# SAM9X75D1GN2 device description
Architecture: ARM926EJ-S; Family: SAM9; Series: SAM9X7
Registers are 32-bit, read-write, reset 0x0 unless marked. A register's access mark holds for its fields unless they carry their own. Offsets are from the block's base; [hi:lo] are bit positions; lines under a group give offsets from that group; {n}, {i} and the like mark numbered series; 'fields as' and 'values as' point back to an identical list.

## ISC — Image Sensor Controller
Instances: ISC 0xF8048000
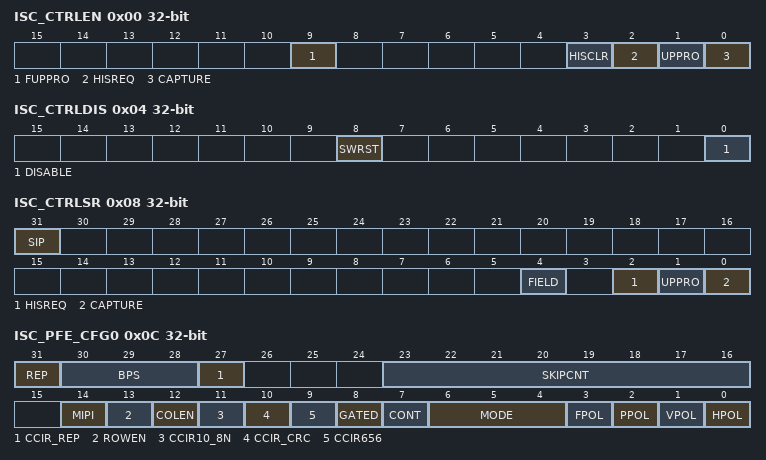
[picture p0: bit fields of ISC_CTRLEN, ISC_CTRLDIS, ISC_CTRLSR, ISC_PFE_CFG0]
0x00 ISC_CTRLEN wo reset not defined (atomic set of ISC_CTRLSR) — Control Enable Register
  [9] FUPPRO — Force Update Color Profile
  [3] HISCLR — Histogram Table Clear
  [2] HISREQ — Histogram Update Request
  [1] UPPRO — Update Color Profile
  [0] CAPTURE — Single Shot or Multiple Frame Capture Input Stream Command
0x04 ISC_CTRLDIS wo reset not defined (atomic clear of ISC_CTRLSR) — Control Disable Register
  [8] SWRST — Software Reset
  [0] DISABLE — End Capture At Next Vertical Synchronization Detection
0x08 ISC_CTRLSR ro — Control Status Register
  [31] SIP — Synchronization In Progress
    0=The double domain synchronization is terminated; 1=The double domain synchronization is in progress
  [4] FIELD — Field Status (only relevant when the video stream is interlaced)
    0=The current field/segment is a top field; 1=The current field/segment is a bottom field
  [2] HISREQ — Histogram Request Pending
    0=There is no histogram pending request; 1=Indicates that the histogram request is still pending
  [1] UPPRO — Profile Update Pending
    0=There is no profile update pending request; 1=Indicates that the profile update request is still pending
  [0] CAPTURE — Capture Pending
    0=Capture mode is disabled; 1=Capture is pending
0x0C ISC_PFE_CFG0 — Parallel Front End Configuration 0 Register
  [31] REP — Up Multiply with Replication
    0=Unused bits are stuck at 0; 1=Unused bits are copied from MSB
  [30:28] BPS — Bits Per Sample
    0=TWELVE (12-bit input); 1=ELEVEN (11-bit input); 2=TEN (10-bit input); 3=NINE (9-bit input); 4=EIGHT (8-bit input); 5=FORTY (40-bit input (used for MIPI formats up to forty bits per pixel))
  [27] CCIR_REP — CCIR Replication
    values as REP
  [23:16] SKIPCNT — Frame Skipping Counter
  [14] MIPI — MIPI Interface Connection
    0=Input data come from the physical parallel interface; 1=Input data come from the physical MIPI interface
  [13] ROWEN — Row Cropping Enable
    0=Row Cropping is disabled; 1=Row Cropping is enabled
  [12] COLEN — Column Cropping Enable
    0=Column Cropping is disabled; 1=Column Cropping is enabled
  [11] CCIR10_8N — CCIR 10 bits or 8 bits
    0=8-bit mode; 1=10-bit mode
  [10] CCIR_CRC — CCIR656 CRC Decoder
    0=Embedded CRC is discarded; 1=Embedded CRC is decoded
  [9] CCIR656 — CCIR656 input mode
    0=HSYNC and VSYNC signals are used to synchronize the input stream; 1=Embedded synchronization is used
  [8] GATED — Gated input clock
    0=The external pixel clock is free running; 1=The external pixel clock is gated
  [7] CONT — Continuous Acquisition
    0=Single Shot mode; 1=Video mode
  [6:4] MODE — Parallel Front End Mode
    0=PROGRESSIVE (Video source is progressive.); 1=DF_TOP (Video source is interlaced, two fields are captured starting with top field.); 2=DF_BOTTOM (Video source is interlaced, two fields are captured starting with bottom field.); 3=DF_IMMEDIATE (Video source is interlaced, two fields are captured immediately.); 4=SF_TOP (Video source is interlaced, one field is captured starting with the top field.); 5=SF_BOTTOM (Video source is interlaced, one field is captured starting with the bottom field.); 6=SF_IMMEDIATE (Video source is interlaced, one field is captured starting immediately.)
  [3] FPOL — Field Polarity
    0=Top field is sampled when F value is 0; Bottom field is sampled when F value is 1; 1=Top field is sampled when F value is 1; Bottom field is sampled when F value is 0
  [2] PPOL — Pixel Clock Polarity
    0=The pixel stream is sampled on the rising edge of the pixel clock; 1=The pixel stream is sampled on the falling edge of the pixel clock
  [1] VPOL — Vertical Synchronization Polarity
    0=VSYNC signal is active high, i.e. valid pixels are sampled when VSYNC is asserted.; 1=VSYNC signal is active low, i.e. valid pixels are sampled when VSYNC is deasserted.
  [0] HPOL — Horizontal Synchronization Polarity
    0=HSYNC signal is active high, i.e. valid pixels are sampled when HSYNC is asserted.; 1=HSYNC signal is active low, i.e. valid pixels are sampled when HSYNC is deasserted.
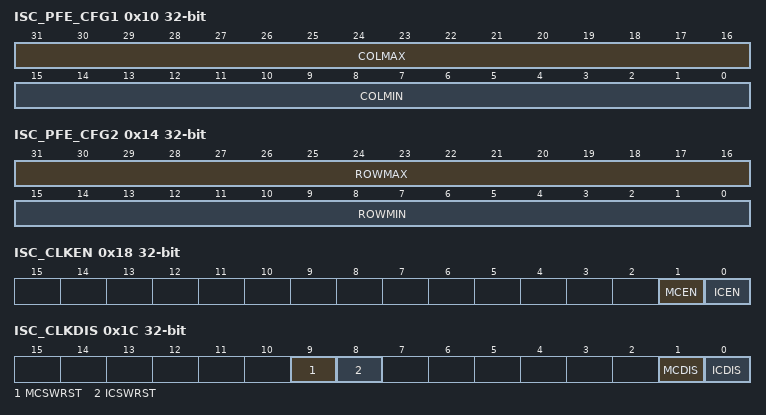
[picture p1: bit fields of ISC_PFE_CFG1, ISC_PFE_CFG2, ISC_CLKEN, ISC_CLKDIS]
0x10 ISC_PFE_CFG1 — Parallel Front End Configuration 1 Register
  [31:16] COLMAX — Column Maximum Limit
  [15:0] COLMIN — Column Minimum Limit
0x14 ISC_PFE_CFG2 — Parallel Front End Configuration 2 Register
  [31:16] ROWMAX — Row Maximum Limit
  [15:0] ROWMIN — Row Minimum Limit
0x18 ISC_CLKEN wo reset not defined (atomic set of ISC_CLKSR) — Clock Enable Register
  [1] MCEN — Camera Sensor Clock Domain Enable
    0=No effect; 1=Enables the camera sensor clock
  [0] ICEN — ISP Clock Enable
    0=No effect; 1=Enables the ISP clock
0x1C ISC_CLKDIS wo reset not defined (atomic clear of ISC_CLKSR) — Clock Disable Register
  [9] MCSWRST — Camera Sensor Clock Domain Software Reset
  [8] ICSWRST — ISP Clock Software Reset
  [1] MCDIS — Camera Sensor Clock Domain Disable
  [0] ICDIS — ISP Clock Disable
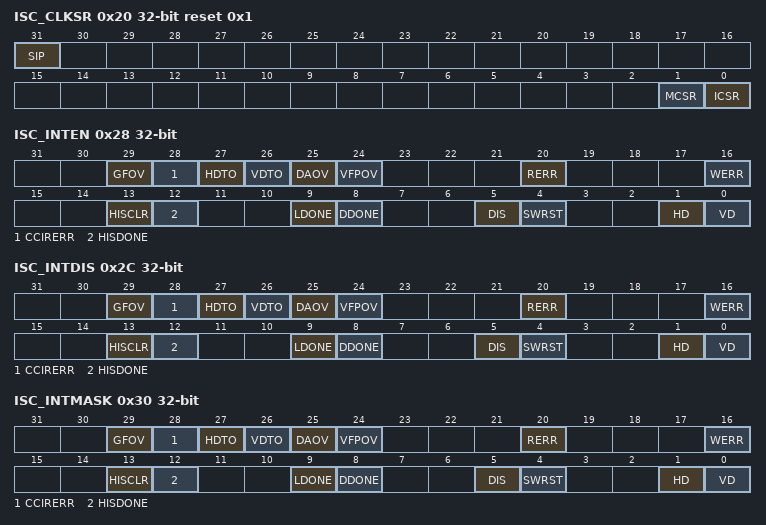
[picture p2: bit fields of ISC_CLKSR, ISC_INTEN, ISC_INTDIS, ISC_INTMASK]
0x20 ISC_CLKSR ro reset 0x1 — Clock Status Register
  [31] SIP — Synchronization In Progress
    0=The double domain synchronization operation is over; 1=The double domain synchronization operation is in progress
  [1] MCSR — Camera Sensor Clock Status Register
    0=The camera sensor clock is disabled; 1=The camera sensor clock is enabled
  [0] ICSR — ISP Clock Status Register
    0=The ISP clock is disabled; 1=The ISP clock is enabled
0x24 ISC_CLKCFG — Clock Configuration Register
  [23:16] MCDIV — Camera Sensor Reference Clock Divider
0x28 ISC_INTEN wo reset not defined (atomic set of ISC_INTSR) — Interrupt Enable Register
  [29] GFOV — Input FIFO Overflow Interrupt Enable
  [28] CCIRERR — CCIR Decoder Error Interrupt Enable
  [27] HDTO — Horizontal Synchronization Timeout Interrupt Enable
  [26] VDTO — Vertical Synchronization Timeout Interrupt Enable
  [25] DAOV — Data Overflow Interrupt Enable
  [24] VFPOV — Vertical Front Porch Overflow Interrupt Enable
  [20] RERR — Read Channel Error Interrupt Enable
  [16] WERR — Write Channel Error Interrupt Enable
  [13] HISCLR — Histogram Clear Interrupt Enable
  [12] HISDONE — Histogram Completed Interrupt Enable
  [9] LDONE — DMA List Done Interrupt Enable
  [8] DDONE — DMA Done Interrupt Enable
  [5] DIS — Disable Completed Interrupt Enable
  [4] SWRST — Software Reset Completed Interrupt Enable
  [1] HD — Horizontal Synchronization Detection Interrupt Enable
  [0] VD — Vertical Synchronization Detection Interrupt Enable
0x2C ISC_INTDIS wo reset not defined (atomic clear of ISC_INTSR) — Interrupt Disable Register
  [29] GFOV — FIFO Overflow Interrupt Disable
  [28] CCIRERR — CCIR Decoder Error Interrupt Disable
  [27] HDTO — Horizontal Synchronization Timeout Interrupt Disable
  [26] VDTO — Vertical Synchronization Timeout Interrupt Disable
  [25] DAOV — Data Overflow Interrupt Disable
  [24] VFPOV — Vertical Front Porch Overflow Interrupt Disable
  [20] RERR — Read Channel Error Interrupt Disable
  [16] WERR — Write Channel Error Interrupt Disable
  [13] HISCLR — Histogram Clear Interrupt Disable
  [12] HISDONE — Histogram Completed Interrupt Disable
  [9] LDONE — DMA List Done Interrupt Disable
  [8] DDONE — DMA Done Interrupt Disable
  [5] DIS — Disable Completed Interrupt Disable
  [4] SWRST — Software Reset Completed Interrupt Disable
  [1] HD — Horizontal Synchronization Detection Interrupt Disable
  [0] VD — Vertical Synchronization Detection Interrupt Disable
0x30 ISC_INTMASK ro — Interrupt Mask Register
  [29] GFOV — FIFO Overflow Interrupt Mask
  [28] CCIRERR — CCIR Decoder Error Interrupt Mask
  [27] HDTO — Horizontal Synchronization Timeout Interrupt Mask
  [26] VDTO — Vertical Synchronization Timeout Interrupt Mask
  [25] DAOV — Data Overflow Interrupt Mask
  [24] VFPOV — Vertical Front Porch Overflow Interrupt Mask
  [20] RERR — Read Channel Error Interrupt Mask
  [16] WERR — Write Channel Error Interrupt Mask
  [13] HISCLR — Histogram Clear Interrupt Mask
  [12] HISDONE — Histogram Completed Interrupt Mask
  [9] LDONE — DMA List Done Interrupt Mask
  [8] DDONE — DMA Done Interrupt Mask
  [5] DIS — Disable Completed Interrupt Mask
  [4] SWRST — Software Reset Completed Interrupt Mask
  [1] HD — Horizontal Synchronization Detection Interrupt Mask
  [0] VD — Vertical Synchronization Detection Interrupt Mask
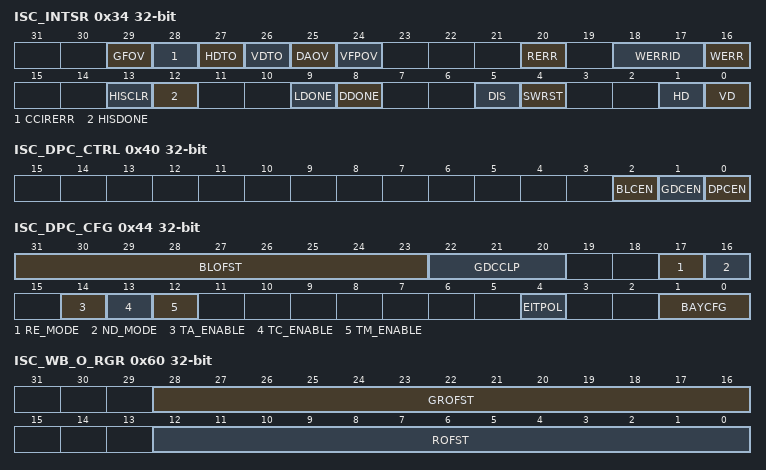
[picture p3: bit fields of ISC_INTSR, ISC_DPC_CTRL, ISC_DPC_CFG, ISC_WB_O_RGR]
0x34 ISC_INTSR ro — Interrupt Status Register
  [29] GFOV — FIFO Overflow Interrupt (relevant if MIPI interface is not selected) (cleared on read)
    0=No FIFO overflow detected since the last read of the Interrupt Status register; 1=A FIFO overflow has been detected
  [28] CCIRERR — CCIR Decoder Error Interrupt (cleared on read)
    0=No CCIR CRC error detected since the last read of the Interrupt Status register; 1=A CCIR CRC error has been detected
  [27] HDTO — Horizontal Synchronization Timeout Interrupt (cleared on read)
    0=Horizontal synchronization is detected since the last reset of the Interrupt Status register; 1=No horizontal synchronization is detected
  [26] VDTO — Vertical Synchronization Timeout Interrupt (cleared on read)
    0=A vertical synchronization is detected since the last reset of the Interrupt Status register; 1=No vertical synchronization is detected
  [25] DAOV — Data Overflow Interrupt (cleared on read)
    0=No data overflow error occurred since the last reset of the Interrupt Status register; 1=A data overflow occurred
  [24] VFPOV — Vertical Front Porch Overflow Interrupt (cleared on read)
    0=No vertical front porch error occurred since the last read of the Interrupt Status register; 1=The vertical synchronization has been detected but the DMA channel is still busy
  [20] RERR — Read Channel Error Interrupt (cleared on read)
    0=No read channel error since the last read of the Interrupt Status register; 1=A read channel error occurred when the ISC read the descriptor
  [18:17] WERRID — Write Channel Error Identifier
    0=CH0 (An error occurred for Channel 0 (RAW/RGB/Y)); 1=CH1 (An error occurred for Channel 1 (CbCr/Cb)); 2=CH2 (An error occurred for Channel 2 (Cr)); 3=WB (Write back channel error)
  [16] WERR — Write Channel Error Interrupt (cleared on read)
    0=No write channel error since the last read of the Interrupt Status register; 1=A write channel error occurred
  [13] HISCLR — Histogram Clear Interrupt (cleared on read)
    0=No Histogram Clear interrupt has been raised since the last read of the Interrupt Status register; 1=The Histogram Clear interrupt has occurred
  [12] HISDONE — Histogram Completed Interrupt (cleared on read)
    0=No Histogram Completed interrupt has been raised since the last read of the Interrupt Status register; 1=The Histogram Completed interrupt has occurred
  [9] LDONE — DMA List Done Interrupt (cleared on read)
    0=No DMA List Done interrupt has occurred since the last read of the Interrupt Status register; 1=The DMA List Done interrupt has occurred
  [8] DDONE — DMA Done Interrupt (cleared on read)
    0=No DMA Transfer Done interrupt has occurred since the last read of the Interrupt Status register; 1=The DMA Transfer Done interrupt has occurred
  [5] DIS — Disable Completed Interrupt (cleared on read)
    0=The disable has not occurred since the last read of the Interrupt Status register; 1=The disable has completed
  [4] SWRST — Software Reset Completed Interrupt (cleared on read)
    0=No software reset completion since the last read of the Interrupt Status register; 1=The software reset has completed
  [1] HD — Horizontal Synchronization Detected Interrupt (cleared on read)
    0=No horizontal synchronization detection since the last read of the Interrupt Status register; 1=A horizontal synchronization has been detected
  [0] VD — Vertical Synchronization Detected Interrupt (cleared on read)
    0=No vertical synchronization detection since the last read of the Interrupt Status register; 1=A vertical synchronization has been detected
0x40 ISC_DPC_CTRL — Defective Pixel Correction Control Register
  [2] BLCEN — Black Level Correction Enable
    0=Black level correction is disabled; 1=Black level correction is enabled
  [1] GDCEN — Green Disparity Correction Enable
    0=Green disparity correction is disabled; 1=Green disparity correction is enabled
  [0] DPCEN — Defective Pixel Correction Enable
    0=Defective pixel correction is disabled; 1=Defective pixel correction is enabled
0x44 ISC_DPC_CFG — Defective Pixel Correction Configuration Register
  [31:23] BLOFST — Black Level Offset Value
  [22:20] GDCCLP — Green Disparity Clipping Value
  [17] RE_MODE — Replacement Algorithm
    0=Median pixel is used; 1=Average pixel is used
  [16] ND_MODE — Noise Detection Mode
    0=At least one detector flag is necessary to trigger the correction; 1=All detector flags are required to trigger the correction
  [14] TA_ENABLE — Average Threshold Enable
    0=Average detector is disabled; 1=Average detector is enabled
  [13] TC_ENABLE — Closest Pixels Threshold Enable
    0=Closest Pixels detector is disabled; 1=Closest Pixels detector is enabled
  [12] TM_ENABLE — Median Threshold Enable
    0=Median detector is disabled; 1=Median detector is enabled
  [4] EITPOL — Edge Interpolation
    0=No edge interpolation is performed; 1=Edge interpolation is performed
  [1:0] BAYCFG — Color Filter Array Pattern
    0=GRGR (Starting row configuration is G R G R (red row)); 1=RGRG (Starting row configuration is R G R G (red row)); 2=GBGB (Starting row configuration is G B G B (blue row)); 3=BGBG (Starting row configuration is B G B G (blue row))
0x48 ISC_DPC_THRESHM — Defective Pixel Correction Threshold M Register
  [11:0] THRESHM — Median Threshold
0x4C ISC_DPC_THRESHC — Defective Pixel Correction Threshold C Register
  [11:0] THRESHC — Closest Pixel Threshold
0x50 ISC_DPC_THRESHA — Defective Pixel Correction Threshold A Register
  [11:0] THRESHA — Average Threshold
0x54 ISC_DPC_SR ro — Defective Pixel Correction Status Register
  [23:0] COUNTER — Defective Pixel Counter (cleared on read)
0x58 ISC_WB_CTRL — White Balance Control Register
  [0] ENABLE — White Balance Enable
    0=The white balance is disabled; 1=The white balance is enabled
0x5C ISC_WB_CFG — White Balance Configuration Register
  [1:0] BAYCFG — White Balance Bayer Configuration (Pixel Color Pattern)
    0=GRGR (Starting Row configuration is G R G R (Red Row)); 1=RGRG (Starting Row configuration is R G R G (Red Row)); 2=GBGB (Starting Row configuration is G B G B (Blue Row)); 3=BGBG (Starting Row configuration is B G B G (Blue Row))
0x60 ISC_WB_O_RGR — White Balance Offset for R, GR Register
  [28:16] GROFST — Offset Green Component for Red Row (signed 13 bits 1:12:0)
  [12:0] ROFST — Offset Red Component (signed 13 bits 1:12:0)
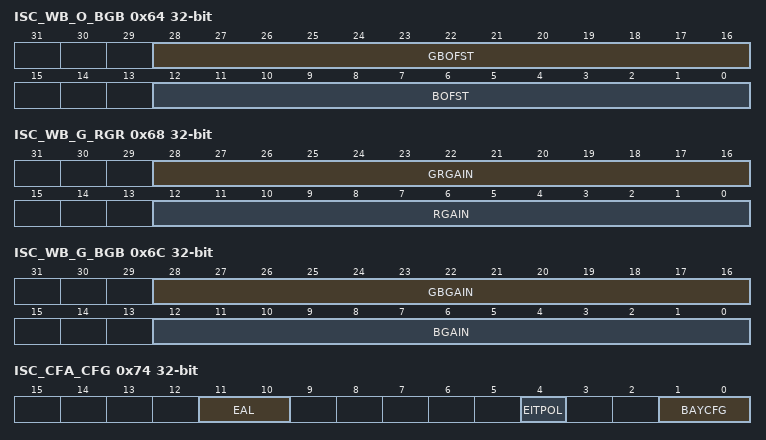
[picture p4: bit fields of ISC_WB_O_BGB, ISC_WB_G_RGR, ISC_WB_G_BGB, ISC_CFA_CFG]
0x64 ISC_WB_O_BGB — White Balance Offset for B, GB Register
  [28:16] GBOFST — Offset Green Component for Blue Row (signed 13 bits, 1:12:0)
  [12:0] BOFST — Offset Blue Component (signed 13 bits, 1:12:0)
0x68 ISC_WB_G_RGR — White Balance Gain for R, GR Register
  [28:16] GRGAIN — Green Component (Red row) Gain (unsigned 13 bits, 0:4:9)
  [12:0] RGAIN — Red Component Gain (unsigned 13 bits, 0:4:9)
0x6C ISC_WB_G_BGB — White Balance Gain for B, GB Register
  [28:16] GBGAIN — Green Component (Blue Row) Gain (unsigned 13 bits, 0:4:9)
  [12:0] BGAIN — Blue Component Gain (unsigned 13 bits, 0:4:9)
0x70 ISC_CFA_CTRL — Color Filter Array Control Register
  [0] ENABLE — Color Filter Array Interpolation Enable
    0=Color Filter Array Interpolation is disabled; 1=Color Filter Array Interpolation is enabled
0x74 ISC_CFA_CFG — Color Filter Array Configuration Register
  [11:10] EAL — Green Channel Edge Adaptive Level
    0=GLINEAR (Green plane is linearly interpolated.); 1=GMEAN (Green plane is the mean value between the linearly interpolated plane and adaptive method plane.); 2=GADAPTIVE (Green plane is interpolated with edge adaptive method.)
  [4] EITPOL — Edge Interpolation
    0=Edges are not interpolated; 1=Edge interpolation is performed
  [1:0] BAYCFG — Bayer Color Filter Array Pattern
    0=GRGR (Starting row configuration is G R G R (red row)); 1=RGRG (Starting row configuration is R G R G (red row); 2=GBGB (Starting row configuration is G B G B (blue row)); 3=BGBG (Starting row configuration is B G B G (blue row))
0x78 ISC_CC_CTRL — Color Correction Control Register
  [0] ENABLE — Color Correction Enable
    0=Color correction is disabled; 1=Color correction is enabled
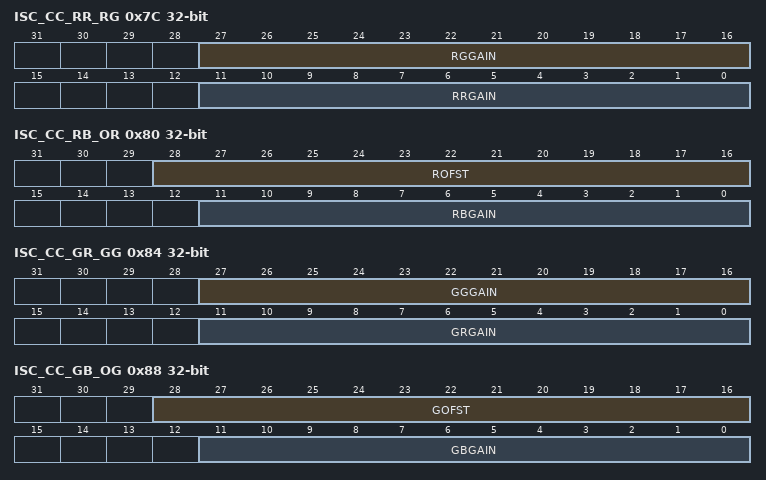
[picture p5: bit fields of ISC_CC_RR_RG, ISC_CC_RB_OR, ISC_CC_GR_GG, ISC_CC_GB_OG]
0x7C ISC_CC_RR_RG — Color Correction RR RG Register
  [27:16] RGGAIN — Green Gain for Red Component (signed 12 bits, 1:3:8)
  [11:0] RRGAIN — Red Gain for Red Component (signed 12 bits, 1:3:8)
0x80 ISC_CC_RB_OR — Color Correction RB OR Register
  [28:16] ROFST — Red Component Offset (signed 13 bits, 1:12:0)
  [11:0] RBGAIN — Blue Gain for Red Component (signed 12 bits, 1:3:8)
0x84 ISC_CC_GR_GG — Color Correction GR GG Register
  [27:16] GGGAIN — Green Gain for Green Component (signed 12 bits, 1:3:8)
  [11:0] GRGAIN — Red Gain for Green Component (signed 12 bits, 1:3:8)
0x88 ISC_CC_GB_OG — Color Correction GB OG Register
  [28:16] GOFST — Green Component Offset (signed 13 bits, 1:12:0)
  [11:0] GBGAIN — Blue Gain for Green Component (signed 12 bits, 1:3:8)
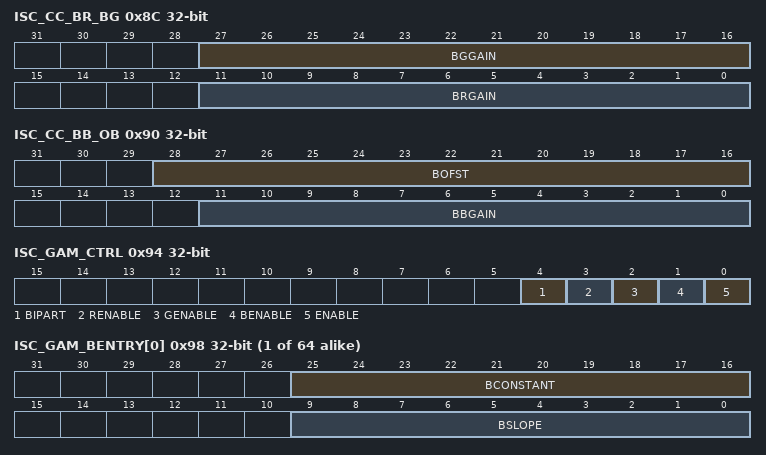
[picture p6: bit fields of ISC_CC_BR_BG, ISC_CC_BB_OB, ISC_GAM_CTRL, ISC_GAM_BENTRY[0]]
0x8C ISC_CC_BR_BG — Color Correction BR BG Register
  [27:16] BGGAIN — Green Gain for Blue Component (signed 12 bits, 1:3:8)
  [11:0] BRGAIN — Red Gain for Blue Component (signed 12 bits, 1:3:8)
0x90 ISC_CC_BB_OB — Color Correction BB OB Register
  [28:16] BOFST — Blue Component Offset (signed 13 bits, 1:12:0)
  [11:0] BBGAIN — Blue Gain for Blue Component (signed 12 bits, 1:3:8)
0x94 ISC_GAM_CTRL — Gamma Correction Control Register
  [4] BIPART — Bipartite Table Configuration
    0=Bipartite table is disabled. There are 64 points of interpolation from 0 to 4095.; 1=Bipartite table is enabled. There are 32 points of interpolation (spacing is 8) from 0 to 255, then there are 30 points of interpolation from 256 to 4095.
  [3] RENABLE — Gamma Correction Enable for R Channel
    0=12-bit to 10-bit compression is performed skipping two bits; 1=Piecewise interpolation is used to perform 12-bit to 10-bit compression for the red channel
  [2] GENABLE — Gamma Correction Enable for G Channel
    0=12-bit to 10-bit compression is performed skipping two bits; 1=Piecewise interpolation is used to perform 12-bit to 10-bit compression for the green channel
  [1] BENABLE — Gamma Correction Enable for B Channel
    0=12-bit to 10-bit compression is performed skipping two bits; 1=Piecewise interpolation is used to perform 112-bit to 10-bit compression for the blue channel
  [0] ENABLE — Gamma Correction Enable
    0=Gamma correction is disabled; 1=Gamma correction is enabled
{0x98+4i} ISC_GAM_BENTRY[{i}] (i=0..63) — Gamma Correction Blue Entry x
  [25:16] BCONSTANT — Blue Color Constant for Piecewise Interpolation (unsigned 10 bits 0:10:0)
  [9:0] BSLOPE — Blue Color Slope for Piecewise Interpolation (signed 10 bits 1:3:6)
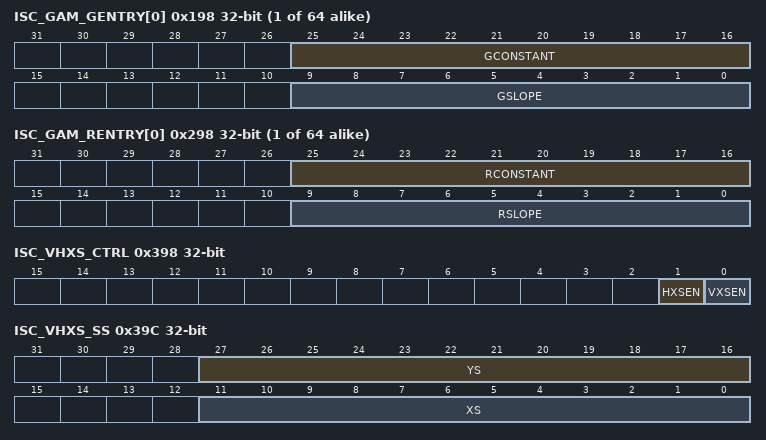
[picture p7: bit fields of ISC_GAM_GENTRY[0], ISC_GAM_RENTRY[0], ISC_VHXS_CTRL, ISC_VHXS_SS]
{0x198+4i} ISC_GAM_GENTRY[{i}] (i=0..63) — Gamma Correction Green Entry x
  [25:16] GCONSTANT — Green Color Constant for Piecewise Interpolation (unsigned 10 bits 0:10:0)
  [9:0] GSLOPE — Green Color Slope for Piecewise Interpolation (signed 10 bits 1:3:6)
{0x298+4i} ISC_GAM_RENTRY[{i}] (i=0..63) — Gamma Correction Red Entry x
  [25:16] RCONSTANT — Red Color Constant for Piecewise Interpolation (unsigned 10 bits 0:10:0)
  [9:0] RSLOPE — Red Color Slope for Piecewise Interpolation (signed 10 bits 1:3:6)
0x398 ISC_VHXS_CTRL — VHXS Control Register
  [1] HXSEN — Horizontal Scaler Enable
    0=Horizontal scaler is disabled; 1=Horizontal scaler is enabled
  [0] VXSEN — Vertical Scaler Enable
    0=Vertical scaler is disabled; 1=Vertical scaler is enabled
0x39C ISC_VHXS_SS — VHXS Source Size Register
  [27:16] YS — Source Image Vertical Size
  [11:0] XS — Source Image Horizontal Size
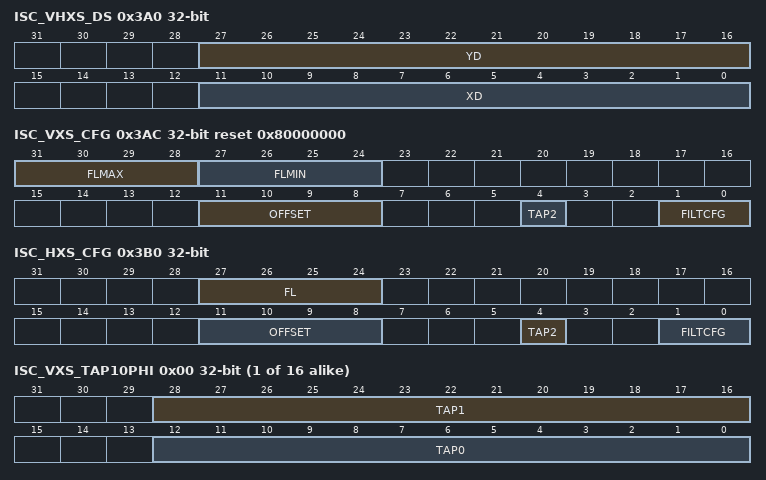
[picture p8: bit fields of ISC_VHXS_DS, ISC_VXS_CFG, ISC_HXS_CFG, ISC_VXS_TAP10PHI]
0x3A0 ISC_VHXS_DS — VHXS Destination Size Register
  [27:16] YD — Destination Image Vertical Size
  [11:0] XD — Destination Image Horizontal Size
0x3A4 ISC_VXS_FACT — VXS Scaling Factor Register
  [23:0] VFACT — Vertical Scaling Factor
0x3A8 ISC_HXS_FACT — HXS Scaling Factor Register
  [23:0] HFACT — Horizontal Scaling Factor
0x3AC ISC_VXS_CFG reset 0x80000000 — VXS Configuration Register
  [31:28] FLMAX — Flush Latency Max
  [27:24] FLMIN — Flush Latency Min
  [11:8] OFFSET — Resampling Default Phase
  [4] TAP2 — Bilinear Interpolation
    0=Custom tap values are used (see Section 8.47 "ISC VXS TAP10 Phase x [x = 0..15] Register"); 1=Bilinear interpolation is used
  [1:0] FILTCFG — Vertical Filter Initial Configuration
0x3B0 ISC_HXS_CFG — HXS Configuration Register
  [27:24] FL — Flush Latency
  [11:8] OFFSET — Resampling Default Phase
  [4] TAP2 — Bilinear Interpolation
    0=Custom tap values are used (see Section 8.49 "ISC HXS TAP10 Phase x [x = 0..15] Register"); 1=Bilinear interpolation is used
  [1:0] FILTCFG — Horizontal Filter Initial Configuration
{0x3B4+8i} ISC_VXS_TAP[{i}] (i=0..15) group
  0x00 ISC_VXS_TAP10PHI — VXS TAP10 Phase Register
    [28:16] TAP1 — Vertical Filter Tap 1 Coefficient
    [12:0] TAP0 — Vertical Filter Tap 0 Coefficient
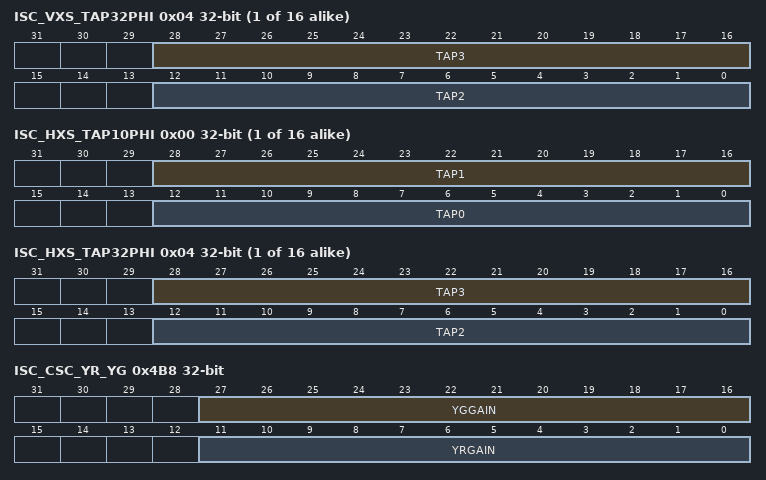
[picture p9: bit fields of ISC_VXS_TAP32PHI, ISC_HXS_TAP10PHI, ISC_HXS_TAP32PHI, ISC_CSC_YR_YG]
  0x04 ISC_VXS_TAP32PHI — VXS TAP32 Phase Register
    [28:16] TAP3 — Vertical Filter Tap 3 Coefficient
    [12:0] TAP2 — Vertical Filter Tap 2 Coefficient
{0x434+8i} ISC_HXS_TAP[{i}] (i=0..15) group
  0x00 ISC_HXS_TAP10PHI — HXS TAP10 Phase Register
    fields as ISC_VXS_TAP[0].ISC_VXS_TAP10PHI
  0x04 ISC_HXS_TAP32PHI — HXS TAP32 Phase Register
    fields as ISC_VXS_TAP[0].ISC_VXS_TAP32PHI
0x4B4 ISC_CSC_CTRL — Color Space Conversion Control Register
  [0] ENABLE — RGB to YCbCr Color Space Conversion Enable
    0=Color space conversion is disabled; 1=Color space conversion is enabled
0x4B8 ISC_CSC_YR_YG — Color Space Conversion YR, YG Register
  [27:16] YGGAIN — Green Gain for Luminance (signed 12 bits 1:3:8)
  [11:0] YRGAIN — Reg Gain for Luminance (signed 12 bits 1:3:8)
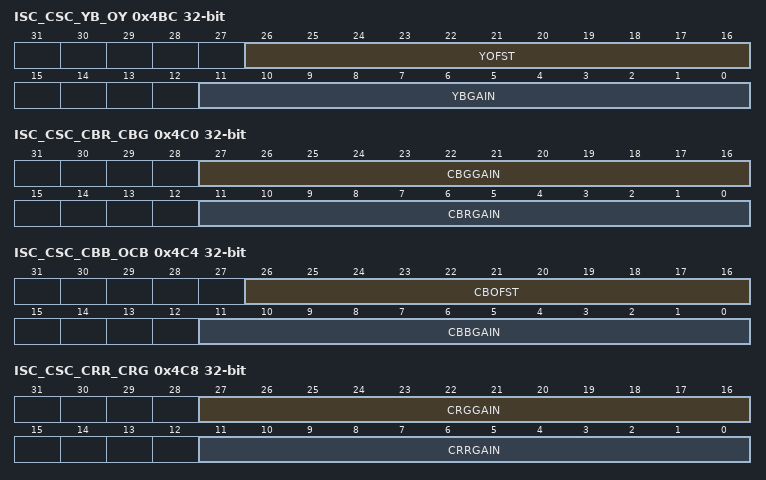
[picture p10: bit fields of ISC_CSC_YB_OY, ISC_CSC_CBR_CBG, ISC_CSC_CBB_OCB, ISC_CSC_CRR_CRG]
0x4BC ISC_CSC_YB_OY — Color Space Conversion YB, OY Register
  [26:16] YOFST — Luminance Offset (11 bits signed 1:10:0)
  [11:0] YBGAIN — Blue Gain for Luminance Component (12 bits signed 1:3:8)
0x4C0 ISC_CSC_CBR_CBG — Color Space Conversion CBR CBG Register
  [27:16] CBGGAIN — Green Gain for Blue Chrominance (signed 12 bits 1:3:8)
  [11:0] CBRGAIN — Red Gain for Blue Chrominance (signed 12 bits, 1:3:8)
0x4C4 ISC_CSC_CBB_OCB — Color Space Conversion CBB OCB Register
  [26:16] CBOFST — Blue Chrominance Offset (signed 11 bits 1:10:0)
  [11:0] CBBGAIN — Blue Gain for Blue Chrominance (signed 12 bits 1:3:8)
0x4C8 ISC_CSC_CRR_CRG — Color Space Conversion CRR CRG Register
  [27:16] CRGGAIN — Green Gain for Red Chrominance (signed 12 bits 1:3:8)
  [11:0] CRRGAIN — Red Gain for Red Chrominance (signed 12 bits 1:3:8)
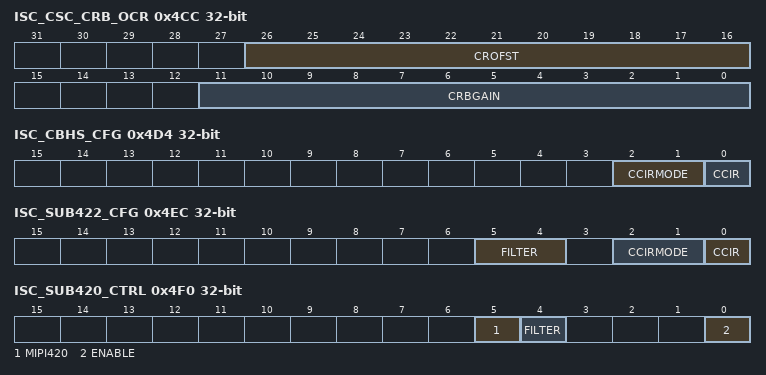
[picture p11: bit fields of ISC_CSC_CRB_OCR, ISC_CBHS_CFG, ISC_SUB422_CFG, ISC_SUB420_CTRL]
0x4CC ISC_CSC_CRB_OCR — Color Space Conversion CRB OCR Register
  [26:16] CROFST — Red Chrominance Offset (signed 11 bits 1:10:0)
  [11:0] CRBGAIN — Blue Gain for Red Chrominance (signed 12 bits 1:3:8)
0x4D0 ISC_CBHS_CTRL — CBHS Control Register
  [0] ENABLE — Contrast, Brightness, Hue and Saturation Control Enable
    0=CBHS control is disabled; 1=CBHS control is enabled
0x4D4 ISC_CBHS_CFG — CBHS Configuration Register
  [2:1] CCIRMODE — CCIR656 Byte Ordering
    0=CBY (Byte ordering Cb0, Y0, Cr0, Y1); 1=CRY (Byte ordering Cr0, Y0, Cb0, Y1); 2=YCB (Byte ordering Y0, Cb0, Y1, Cr0); 3=YCR (Byte ordering Y0, Cr0, Y1, Cb0)
  [0] CCIR — CCIR656 Stream Enable
    0=Raw mode; 1=CCIR656 stream
0x4D8 ISC_CBHS_BRIGHT — CBHS Brightness Register
  [10:0] BRIGHT — Image Brightness Control (signed 11 bits 1:10:0)
0x4DC ISC_CBHS_CONT — CBHS Contrast Register
  [11:0] CONTRAST — Image Contrast (unsigned 12 bits 0:4:8)
0x4E0 ISC_CBHS_HUE — CBHS Hue Register
  [8:0] HUE — Image Hue value (unsigned 9 bits 0:9:0)
0x4E4 ISC_CBHS_SAT — CBHS Saturation Register
  [11:0] SATURATION — Image Saturation Value (unsigned 12 bits 0:8:4)
0x4E8 ISC_SUB422_CTRL — Subsampling 4:4:4 to 4:2:2 Control Register
  [0] ENABLE — 4:4:4 to 4:2:2 Chrominance Horizontal Subsampling Filter Enable
    0=Subsampler is disabled; 1=Subsampler is enabled
0x4EC ISC_SUB422_CFG — Subsampling 4:4:4 to 4:2:2 Configuration Register
  [5:4] FILTER — Low Pass Filter Selection
    0=FILT0CO (Cosited, {1}); 1=FILT1CE (Centered {1, 1}); 2=FILT2CO (Cosited {1,2,1}); 3=FILT3CE (Centered {1, 3, 3, 1})
  [2:1] CCIRMODE — CCIR656 Byte Ordering
    values as ISC_CBHS_CFG.CCIRMODE
  [0] CCIR — CCIR656 Input Stream
    0=Raw mode; 1=CCIR mode
0x4F0 ISC_SUB420_CTRL — Subsampling 4:2:2 to 4:2:0 Control Register
  [5] MIPI420 — MIPI YUV 420 8-bpp or 10-bpp Even Odd Splitter
    0=Normal mode; 1=When the MIPI interface is selected and the source format is YUV 420 RMS (recommended memory storage), the sub420 submodule routes data lanes depending on the parity of the line received (odd or even)
  [4] FILTER — Interlaced or Progressive Chrominance Filter
    0=Progressive filter {0.5, 0.5}; 1=Field-dependent filter, top field filter is {0.75, 0.25}, bottom field filter is {0.25, 0.75}
  [0] ENABLE — 4:2:2 to 4:2:0 Vertical Subsampling Filter Enable (Center Aligned)
    0=Subsampler disabled; 1=Subsampler enabled
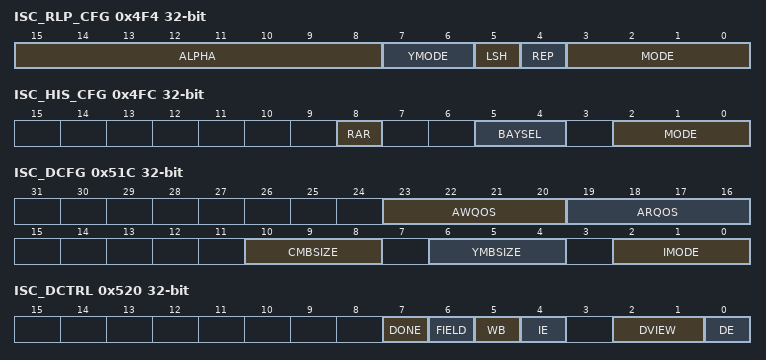
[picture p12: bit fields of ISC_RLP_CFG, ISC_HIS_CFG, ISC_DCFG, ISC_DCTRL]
0x4F4 ISC_RLP_CFG — Rounding, Limiting and Packing Configuration Register
  [15:8] ALPHA — Alpha Value for Alpha-enabled RGB Mode
  [7:6] YMODE — YCbCr Memory Mapping Configuration Mode
    0=RLP_YCBYCR (Byte 0 is Cr, Byte 1 is Y(n), Byte 2 is Cb, Byte 3 is Y(n+1)); 1=RLP_YCRYCB (Byte 0 is Cb, Byte 1 is Y(n), Byte 2 is Cb, Byte 3 is Y(n+1)); 2=RLP_CBYCRY (Byte 0 is Y(n), Byte 1 is Cr, Byte 2 is Y(n+1), Byte 3 is Cb); 3=RLP_CRYCBY (Byte 0 is Y (n), Byte 1 is Cb, Byte 2 is Y(n+1), Byte 3 is Cr)
  [5] LSH — Logical Left Shift for Pixel to 16-bit Container Mapping
    0=Logical left shift is disabled; 1=Pixel value is left-justified in a 16-bit container
  [4] REP — Pixel Expansion with Replication Logic
    0=Replication is disabled; 1=Replication is enabled
  [3:0] MODE — Rounding, Limiting and Packing Mode
    {v}=DAT{v+8} ({v+8}-bit data) (v=0..4); 5=DATY8 (8-bit luminance only); 6=DATY10 (10-bit luminance only); 7=ARGB444 (12-bit RGB+4-bit Alpha (MSB)); 8=ARGB555 (15-bit RGB+1-bit Alpha (MSB)); 9=RGB565 (16-bit RGB); 10=ARGB32 (24-bits RGB mode+8-bit Alpha); 11=YYCC (YCbCr mode (full range, [0-255])); 12=YYCC_LIMITED (YCbCr mode (limited range)); 13=YCYC (Y(n+1)CbY(n)Cr 422 interleaved full range per component 8-bit [0-255]); 14=YCYC_LIMITED (Y(n+1)CbY(n)Cr 422 interleaved limited range per component 8-bit); 15=BYPASS (32-bit input is sampled and written to the rlp output port. Select this mode for MIPI RMS mode.)
0x4F8 ISC_HIS_CTRL — Histogram Control Register
  [0] ENABLE — Histogram Sub Module Enable
    0=Histogram disabled; 1=Histogram enabled
0x4FC ISC_HIS_CFG — Histogram Configuration Register
  [8] RAR — Histogram Reset After Read
    0=Reset after Read mode is disabled; 1=Reset after Read mode is enabled
  [5:4] BAYSEL — Bayer Color Component Selection
    0=GRGR (Starting row configuration is G R G R (red row)); 1=RGRG (Starting row configuration is R G R G (red row)); 2=GBGB (Starting row configuration is G B G B (blue row); 3=BGBG (Starting row configuration is B G B G (blue row))
  [2:0] MODE — Histogram Operating Mode
    0=GR (Gr sampling); 1=R (R sampling); 2=GB (Gb sampling); 3=B (B sampling); 4=Y (Luminance-only mode); 5=RAW (Raw sampling); 6=YCCIR656 (Luminance only with CCIR656 10-bit or 8-bit mode)
0x51C ISC_DCFG — DMA Configuration Register
  [23:20] AWQOS — Write QoS Value
  [19:16] ARQOS — Read QoS Value
  [10:8] CMBSIZE — DMA Memory Burst Size C channel
    0=SINGLE (DMA single access); 1=BEATS4 (4-beat burst access); 2=BEATS8 (8-beat burst access); 3=BEATS16 (16-beat burst access); 4=BEATS32 (32-beat burst access)
  [6:4] YMBSIZE — DMA Memory Burst Size Y channel
    values as CMBSIZE
  [2:0] IMODE — DMA Input Mode Selection
    0=PACKED8 (8 bits, single channel packed); 1=PACKED16 (16 bits, single channel packed); 2=PACKED32 (32 bits, single channel packed); 3=YC422SP (32 bits, dual channel); 4=YC422P (32 bits, triple channel); 5=YC420SP (32 bits, dual channel); 6=YC420P (32 bits, triple channel)
0x520 ISC_DCTRL — DMA Control Register
  [7] DONE — Descriptor Processing Status
    0=Descriptor not processed yet; 1=Descriptor processed
  [6] FIELD — Value of Captured Frame Field Signal
    0=Field value is 0; 1=Field value is 1
  [5] WB — Write Back Operation Enable
    0=Write Back operation is skipped; 1=Write Back operation is performed
  [4] IE — Interrupt Enable
    0=DMA Done interrupt is generated; 1=DMA Done interrupt is not set
  [2:1] DVIEW — Descriptor View
    0=PACKED (Packed frame buffer (see Table 7-3)); 1=SEMIPLANAR (Semi planar frame buffer (see Table 7-4)); 2=PLANAR (Planar frame buffer (see Table 7-5))
  [0] DE — Descriptor Enable
    0=Descriptor disabled; 1=Descriptor enabled
0x524 ISC_DNDA — DMA Descriptor Address Register
  [31:2] NDA — Next Descriptor Address Register
{0x528+8i} ISC_DAD{i} (i=0..2) — DMA Address {i} Register
  [31:0] AD{i} — Channel {i} Address
{0x52C+8i} ISC_DST{i} (i=0..2) — DMA Stride {i} Register
  [15:0] ST{i} — Channel {i} Stride
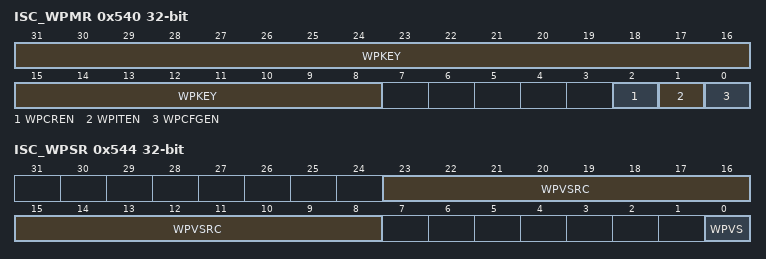
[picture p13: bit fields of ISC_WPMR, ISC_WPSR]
0x540 ISC_WPMR — Write protection Mode Register
  [31:8] WPKEY — Write Protection Key Password
    0x584953=PASSWD (Writing any other value in this field aborts the write operation of the WPCFGEN,WPITEN,WPCREN bits. Always reads as 0.)
  [2] WPCREN — Write Protection Control Registers Enable
    0=Disables the write protection of control registers if WPKEY corresponds to 0x584953 ("XIS" in ASCII); 1=Enables the write protection of control enable/disable registers if WPKEY corresponds to 0x584953 ("XIS" in ASCII)
  [1] WPITEN — Write Protection Interrupt Registers Enable
    0=Disables the write protection of interrupt enable/disable registers if WPKEY corresponds to 0x584953 ("XIS" in ASCII); 1=Enables the write protection of interrupt enable/disable registers if WPKEY corresponds to 0x584953 ("XIS" in ASCII)
  [0] WPCFGEN — Write Protection Configuration Registers Enable
    0=Disables the write protection of configuration registers if WPKEY corresponds to 0x584953 ("XIS" in ASCII); 1=Enables the write protection of configuration registers if WPKEY corresponds to 0x584953 ("XIS" in ASCII)
0x544 ISC_WPSR ro — Write Protection Status Register
  [23:8] WPVSRC — Write Protection Violation Source
  [0] WPVS — Write Protection Violation Status
{0x55C+4i} ISC_HIS_ENTRY[{i}] (i=0..511) ro — Histogram Entry x
  [19:0] COUNT — Entry Counter
Value list ISC_INTSR__WPE: 0=No Write Protection error detected since the last read of the Interrupt Status register; 1=A Write Protection error has been detected
